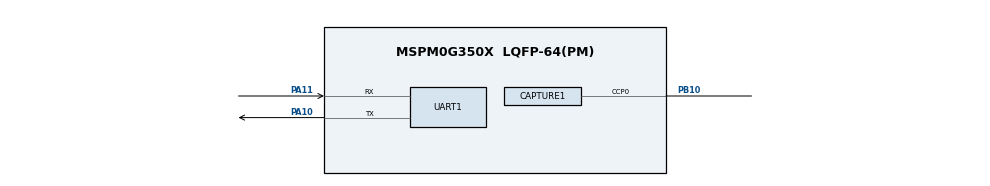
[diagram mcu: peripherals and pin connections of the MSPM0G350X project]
/**
 * @cliArgs --device "MSPM0G350X" --part "Default" --package "LQFP-64(PM)" --product "mspm0_sdk@2.04.00.06"
 * @versions {"tool":"1.22.0+3893"}
 */

/**
 * Import the modules used in this configuration.
 */
const ADC12         = scripting.addModule("/ti/driverlib/ADC12", {}, false);
const ADC121        = ADC12.addInstance();
const CAPTURE       = scripting.addModule("/ti/driverlib/CAPTURE", {}, false);
const CAPTURE1      = CAPTURE.addInstance();
const GPIO          = scripting.addModule("/ti/driverlib/GPIO", {}, false);
const GPIO1         = GPIO.addInstance();
const GPIO2         = GPIO.addInstance();
const GPIO3         = GPIO.addInstance();
const GPIO4         = GPIO.addInstance();
const TIMER         = scripting.addModule("/ti/driverlib/TIMER", {}, false);
const TIMER1        = TIMER.addInstance();
const TIMER2        = TIMER.addInstance();
const UART          = scripting.addModule("/ti/driverlib/UART", {}, false);
const UART1         = UART.addInstance();
const ProjectConfig = scripting.addModule("/ti/project_config/ProjectConfig");

/**
 * Write custom configuration values to the imported modules.
 */
ADC121.$name                             = "ADC12_0";
ADC121.repeatMode                        = true;
ADC121.trigSrc                           = "DL_ADC12_TRIG_SRC_EVENT";
ADC121.adcMem0trig                       = "DL_ADC12_TRIGGER_MODE_TRIGGER_NEXT";
ADC121.powerDownMode                     = "DL_ADC12_POWER_DOWN_MODE_MANUAL";
ADC121.enabledInterrupts                 = ["DL_ADC12_INTERRUPT_DMA_DONE"];
ADC121.configureDMA                      = true;
ADC121.sampCnt                           = 1;
ADC121.enabledDMATriggers                = ["DL_ADC12_DMA_MEM0_RESULT_LOADED"];
ADC121.subChanID                         = 2;
ADC121.sampleTime0                       = "1us";
ADC121.peripheral.$assign                = "ADC0";
ADC121.peripheral.adcPin0.$assign        = "PA27";
ADC121.adcPin0Config.$name               = "ti_driverlib_gpio_GPIOPinGeneric3";
ADC121.DMA_CHANNEL.$name                 = "DMA_CH0";
ADC121.DMA_CHANNEL.addressMode           = "f2b";
ADC121.DMA_CHANNEL.srcLength             = "HALF_WORD";
ADC121.DMA_CHANNEL.dstLength             = "HALF_WORD";
ADC121.DMA_CHANNEL.configureTransferSize = true;
ADC121.DMA_CHANNEL.transferSize          = 1024;
ADC121.DMA_CHANNEL.transferMode          = "FULL_CH_REPEAT_SINGLE";

const Board = scripting.addModule("/ti/driverlib/Board", {}, false);

CAPTURE1.$name                      = "CAPTURE_0";
CAPTURE1.captMode                   = "COMBINED";
CAPTURE1.interrupts                 = ["CC1_DN","ZERO"];
CAPTURE1.timerPeriod                = "2ms";
CAPTURE1.peripheral.$assign         = "TIMG0";
CAPTURE1.peripheral.ccp0Pin.$assign = "PB10";
CAPTURE1.ccp0PinConfig.$name        = "ti_driverlib_gpio_GPIOPinGeneric0";

GPIO1.$name                          = "GPIO_OLED";
GPIO1.associatedPins.create(2);
GPIO1.associatedPins[0].$name        = "PIN_SCL";
GPIO1.associatedPins[0].assignedPort = "PORTA";
GPIO1.associatedPins[0].assignedPin  = "12";
GPIO1.associatedPins[1].$name        = "PIN_SDA";
GPIO1.associatedPins[1].assignedPort = "PORTA";
GPIO1.associatedPins[1].assignedPin  = "13";

GPIO2.$name                          = "GPIO_LEDS";
GPIO2.associatedPins[0].$name        = "USER_LED_1";
GPIO2.associatedPins[0].initialValue = "SET";
GPIO2.associatedPins[0].assignedPort = "PORTA";
GPIO2.associatedPins[0].assignedPin  = "0";

GPIO3.$name                              = "GPIO_SWITCHES";
GPIO3.associatedPins[0].$name            = "USER_SWITCH_1";
GPIO3.associatedPins[0].direction        = "INPUT";
GPIO3.associatedPins[0].assignedPort     = "PORTB";
GPIO3.associatedPins[0].assignedPin      = "21";
GPIO3.associatedPins[0].internalResistor = "PULL_UP";
GPIO3.associatedPins[0].interruptEn      = true;
GPIO3.associatedPins[0].polarity         = "RISE_FALL";

GPIO4.$name                              = "GPIO_RELAY";
GPIO4.associatedPins[0].internalResistor = "PULL_UP";
GPIO4.associatedPins[0].$name            = "USER_RELAY_1";
GPIO4.associatedPins[0].assignedPort     = "PORTB";
GPIO4.associatedPins[0].assignedPin      = "15";

const SYSCTL                 = scripting.addModule("/ti/driverlib/SYSCTL", {}, false);
SYSCTL.forceDefaultClkConfig = true;
SYSCTL.clockTreeEn           = true;

TIMER1.$name                       = "TIMER_0";
TIMER1.timerClkPrescale            = 200;
TIMER1.event1PublisherChannel      = 1;
TIMER1.event1ControllerInterruptEn = ["ZERO_EVENT"];
TIMER1.interrupts                  = ["ZERO"];
TIMER1.timerClkDiv                 = 8;
TIMER1.timerPeriod                 = "1s";
TIMER1.peripheral.$assign          = "TIMA1";

TIMER2.$name                       = "TIMER_1";
TIMER2.timerMode                   = "PERIODIC";
TIMER2.timerPeriod                 = "1us";
TIMER2.timerStartTimer             = true;
TIMER2.event1PublisherChannel      = 2;
TIMER2.event1ControllerInterruptEn = ["ZERO_EVENT"];
TIMER2.peripheral.$assign          = "TIMA0";

UART1.$name                    = "UART_0";
UART1.ovsRate                  = "3";
UART1.uartClkSrc               = "LFCLK";
UART1.peripheral.rxPin.$assign = "PA11";
UART1.peripheral.txPin.$assign = "PA10";
UART1.txPinConfig.$name        = "ti_driverlib_gpio_GPIOPinGeneric1";
UART1.rxPinConfig.$name        = "ti_driverlib_gpio_GPIOPinGeneric2";

ProjectConfig.genLibCMSIS = true;

/**
 * Pinmux solution for unlocked pins/peripherals. This ensures that minor changes to the automatic solver in a future
 * version of the tool will not impact the pinmux you originally saw.  These lines can be completely deleted in order to
 * re-solve from scratch.
 */
ADC121.DMA_CHANNEL.peripheral.$suggestSolution = "DMA_CH0";
Board.peripheral.$suggestSolution              = "DEBUGSS";
Board.peripheral.swclkPin.$suggestSolution     = "PA20";
Board.peripheral.swdioPin.$suggestSolution     = "PA19";
GPIO1.associatedPins[0].pin.$suggestSolution   = "PA12";
GPIO1.associatedPins[1].pin.$suggestSolution   = "PA13";
GPIO2.associatedPins[0].pin.$suggestSolution   = "PA0";
GPIO3.associatedPins[0].pin.$suggestSolution   = "PB21";
GPIO4.associatedPins[0].pin.$suggestSolution   = "PB15";
UART1.peripheral.$suggestSolution              = "UART0";
